# ESP32-S3 register map
Vendor: ESPRESSIF SYSTEMS (SHANGHAI) CO., LTD.; Series: ESP32 S-Series; File version: 22
CPU: Xtensa LX7 r0p0, little endian, no MPU, FPU, 0 interrupt priority bits
Address unit: 32 bits
Registers are 32-bit, read-write, reset 0x0 unless marked. A register's access mark holds for its fields unless they carry their own. Offsets are from the block's base; [hi:lo] are bit positions; {n}, {i} and the like mark numbered series.

## USB_WRAP — USB_WRAP Peripheral
Base 0x60039000
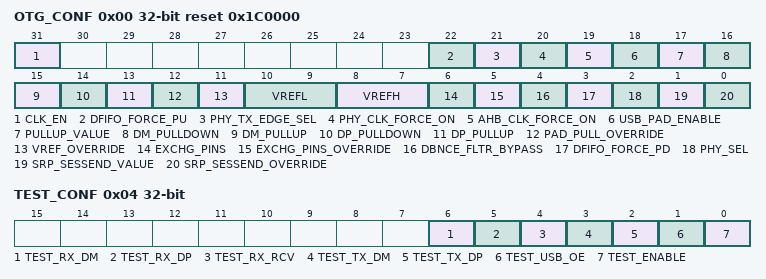
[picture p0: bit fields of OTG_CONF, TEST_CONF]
0x00 OTG_CONF reset 0x1C0000 — USB OTG Wrapper Configure Register
  [31] CLK_EN — Disable auto clock gating of CSR registers
  [22] DFIFO_FORCE_PU — Disable the dfifo to go into low power mode. The data in dfifo will not lost.
  [21] PHY_TX_EDGE_SEL — Select phy tx signal output clock edge. 1'b0: negedge. 1'b1: posedge.
  [20] PHY_CLK_FORCE_ON — Force phy clock always on
  [19] AHB_CLK_FORCE_ON — Force ahb clock always on
  [18] USB_PAD_ENABLE — Enable USB pad function
  [17] PULLUP_VALUE — Controlle pullup value. 1'b0: typical value is 2.4K. 1'b1: typical value is 1.2K.
  [16] DM_PULLDOWN — Controlle USB D+ pulldown
  [15] DM_PULLUP — Controlle USB D+ pullup
  [14] DP_PULLDOWN — Controlle USB D+ pulldown
  [13] DP_PULLUP — Controlle USB D+ pullup
  [12] PAD_PULL_OVERRIDE — Enable software controlle USB D+ D- pullup pulldown
  [11] VREF_OVERRIDE — Enable software controlle input threshold
  [10:9] VREFL — Control single-end input low threshold,0.8V to 1.04V, step 80mV
  [8:7] VREFH — Control single-end input high threshold,1.76V to 2V, step 80mV
  [6] EXCHG_PINS — USB D+ D- exchange. 1'b0: don't change. 1'b1: exchange D+ D-
  [5] EXCHG_PINS_OVERRIDE — Enable software controlle USB D+ D- exchange
  [4] DBNCE_FLTR_BYPASS — Bypass Debounce filters for avalid,bvalid,vbusvalid,session end, id signals
  [3] DFIFO_FORCE_PD — Force the dfifo to go into low power mode. The data in dfifo will not lost.
  [2] PHY_SEL — Select internal external PHY. 1'b0: Select internal PHY. 1'b1: Select external PHY.
  [1] SRP_SESSEND_VALUE — Software over-ride value of srp session end signal.
  [0] SRP_SESSEND_OVERRIDE — This bit is used to enable the software over-ride of srp session end signal. 1'b0: the signal is controlled by the chip input. 1'b1: the signal is controlled by the software.
0x04 TEST_CONF access per field — USB Internal PHY Testing Register
  [6] TEST_RX_DM ro — USB D- rx value in test
  [5] TEST_RX_DP ro — USB D+ rx value in test
  [4] TEST_RX_RCV ro — USB differential rx value in test
  [3] TEST_TX_DM rw — USB D- tx value in test
  [2] TEST_TX_DP rw — USB D+ tx value in test
  [1] TEST_USB_OE rw — USB pad oen in test
  [0] TEST_ENABLE rw — Enable test of the USB pad
0x3FC DATE reset 0x2102010 — Version Control Register
  [31:0] USB_WRAP_DATE — Date register

## XTS_AES — XTS-AES-128 Flash Encryption
Base 0x600CC000
{0x0+4i} PLAIN_{i} (i=0..15) — Plaintext register {i}
  [31:0] PLAIN — Stores the nth 32-bit piece of plaintext.
0x40 LINESIZE — XTS-AES line-size register
  [0] LINESIZE — Configures the data size of one encryption.
0x44 DESTINATION — XTS-AES destination register
  [0] DESTINATION — Configures the type of the external memory. Currently, it must be set to 0, as the Manual Encryption block only supports flash encryption. Errors may occurs if users write 1. 0:flash. 1: external RAM.
0x48 PHYSICAL_ADDRESS
  [29:0] PHYSICAL_ADDRESS — Those bits stores the physical address. If linesize is 16-byte, the physical address should be aligned of 16 bytes. If linesize is 32-byte, the physical address should be aligned of 32 bytes. If linesize is 64-byte, the physical address should be aligned of 64 bytes.
0x4C TRIGGER wo — XTS-AES trigger register
  [0] TRIGGER — Write 1 to activate manual encryption.
0x50 RELEASE wo — XTS-AES release control register
  [0] RELEASE — Write 1 to grant SPI1 access to encrypted result.
0x54 DESTROY wo — XTS-AES destroy control register
  [0] DESTROY — Write 1 to destroy encrypted result.
0x58 STATE ro — XTS-AES status register
  [1:0] STATE — Those bits indicates the status of the Manual Encryption block. 0X0 (XTS_AES_IDLE): idle. 0X1 (XTS_AES_BUSY): busy with encryption. 0X2 (XTS_AES_DONE): encryption is completed, but the encrypted result is not accessible to SPI. 0X3 (XTS_AES_AVAILABLE) encrypted result is accessible and available to SPI.
0x5C DATE reset 0x20200111 — XTS-AES version control register
  [29:0] DATE — Manual Encryption block version information.
